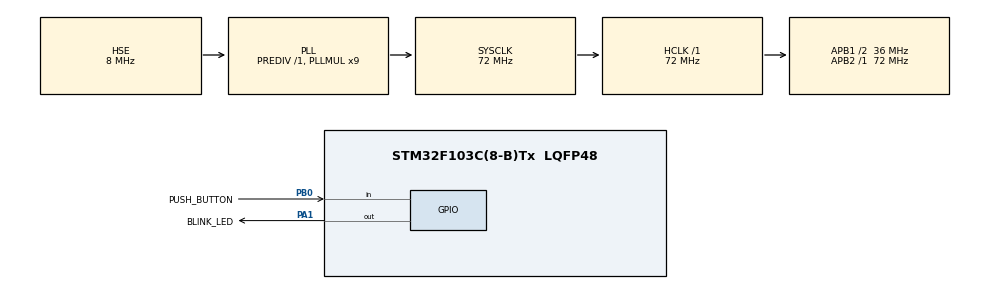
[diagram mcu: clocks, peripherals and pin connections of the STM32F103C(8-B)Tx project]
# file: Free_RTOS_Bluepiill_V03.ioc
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FREERTOS.Tasks01=defaultTask,0,128,StartDefaultTask,Default,NULL,Dynamic,NULL,NULL;ledtask,0,128,LED_Task,Default,NULL,Dynamic,NULL,NULL;buttonTask,0,128,Button_Task,Default,NULL,Dynamic,NULL,NULL
Mcu.Family=STM32F1
Mcu.Name=STM32F103C(8-B)Tx
Mcu.Package=LQFP48
NVIC.PriorityGroup=NVIC_PRIORITYGROUP_4
NVIC.TIM4_IRQn=true\:15\:0\:false\:false\:true\:false\:false\:true\:true
NVIC.TimeBase=TIM4_IRQn
NVIC.TimeBaseIP=TIM4
PA1.GPIO_Label=BLINK_LED
PA1.Signal=GPIO_Output
PA13.Mode=Trace_Asynchronous_SW
PA13.Signal=SYS_JTMS-SWDIO
PA14.Mode=Trace_Asynchronous_SW
PA14.Signal=SYS_JTCK-SWCLK
PB0.GPIO_Label=PUSH_BUTTON
PB0.GPIO_PuPd=GPIO_PULLDOWN
PB0.Signal=GPIO_Input
PB3.Mode=Trace_Asynchronous_SW
PB3.Signal=SYS_JTDO-TRACESWO
PD0-OSC_IN.Mode=HSE-External-Oscillator
PD0-OSC_IN.Signal=RCC_OSC_IN
PD1-OSC_OUT.Mode=HSE-External-Oscillator
PD1-OSC_OUT.Signal=RCC_OSC_OUT
ProjectManager.HeapSize=0x200
ProjectManager.StackSize=0x400
ProjectManager.TargetToolchain=STM32CubeIDE
RCC.AHBFreq_Value=72000000
RCC.APB1CLKDivider=RCC_HCLK_DIV2
RCC.APB1Freq_Value=36000000
RCC.APB1TimFreq_Value=72000000
RCC.APB2Freq_Value=72000000
RCC.APB2TimFreq_Value=72000000
RCC.HCLKFreq_Value=72000000
RCC.PLLMUL=RCC_PLL_MUL9
RCC.PLLSourceVirtual=RCC_PLLSOURCE_HSE
RCC.SYSCLKFreq_VALUE=72000000
RCC.SYSCLKSource=RCC_SYSCLKSOURCE_PLLCLK
RCC.USBFreq_Value=72000000
VP_FREERTOS_VS_CMSIS_V1.Mode=CMSIS_V1
VP_SYS_VS_tim4.Mode=TIM4
board=custom

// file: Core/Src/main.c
/* USER CODE BEGIN Header */
/**
  ******************************************************************************
  * @file           : main.c
  * @brief          : Main program body
  ******************************************************************************
  * @attention
  *
  * Copyright (c) 2024 STMicroelectronics.
  * All rights reserved.
  *
  * This software is licensed under terms that can be found in the LICENSE file
  * in the root directory of this software component.
  * If no LICENSE file comes with this software, it is provided AS-IS.
  *
  ******************************************************************************
  */
/* USER CODE END Header */
#include "main.h"
#include "cmsis_os.h"

osThreadId defaultTaskHandle;
osThreadId ledtaskHandle;
osThreadId buttonTaskHandle;

void SystemClock_Config(void);
static void MX_GPIO_Init(void);
void StartDefaultTask(void const * argument);
void LED_Task(void const * argument);
void Button_Task(void const * argument);

// Variável global para controlar a frequência do LED
uint8_t blinkFrequency = 0;

int main(void)
{

  /* MCU Configuration--------------------------------------------------------*/

  /* Reset of all peripherals, Initializes the Flash interface and the Systick. */
  HAL_Init();

  /* Configure the system clock */
  SystemClock_Config();

  /* Initialize all configured peripherals */
  MX_GPIO_Init();
  /* USER CODE BEGIN 2 */
  // Criar tarefas
      osThreadDef(ButtonTask, Button_Task, osPriorityNormal, 0, 128);
      osThreadCreate(osThread(ButtonTask), NULL);

      osThreadDef(LEDTask, LED_Task, osPriorityNormal, 0, 128);
      osThreadCreate(osThread(LEDTask), NULL);

      // Iniciar o scheduler
      osKernelStart();

  /* USER CODE END 2 */

  /* Create the thread(s) */
  /* definition and creation of defaultTask */
  osThreadDef(defaultTask, StartDefaultTask, osPriorityNormal, 0, 128);
  defaultTaskHandle = osThreadCreate(osThread(defaultTask), NULL);

  /* definition and creation of ledtask */
  osThreadDef(ledtask, LED_Task, osPriorityNormal, 0, 128);
  ledtaskHandle = osThreadCreate(osThread(ledtask), NULL);

  /* definition and creation of buttonTask */
  osThreadDef(buttonTask, Button_Task, osPriorityNormal, 0, 128);
  buttonTaskHandle = osThreadCreate(osThread(buttonTask), NULL);

  /* Start scheduler */
  osKernelStart();

  /* We should never get here as control is now taken by the scheduler */

  /* Infinite loop */
  while (1)
  {

  }
}

void SystemClock_Config(void)
{
  RCC_OscInitTypeDef RCC_OscInitStruct = {0};
  RCC_ClkInitTypeDef RCC_ClkInitStruct = {0};

  /** Initializes the RCC Oscillators according to the specified parameters
  * in the RCC_OscInitTypeDef structure.
  */
  RCC_OscInitStruct.OscillatorType = RCC_OSCILLATORTYPE_HSE;
  RCC_OscInitStruct.HSEState = RCC_HSE_ON;
  RCC_OscInitStruct.HSEPredivValue = RCC_HSE_PREDIV_DIV1;
  RCC_OscInitStruct.HSIState = RCC_HSI_ON;
  RCC_OscInitStruct.PLL.PLLState = RCC_PLL_ON;
  RCC_OscInitStruct.PLL.PLLSource = RCC_PLLSOURCE_HSE;
  RCC_OscInitStruct.PLL.PLLMUL = RCC_PLL_MUL9;
  if (HAL_RCC_OscConfig(&RCC_OscInitStruct) != HAL_OK)
  {
    Error_Handler();
  }

  /** Initializes the CPU, AHB and APB buses clocks
  */
  RCC_ClkInitStruct.ClockType = RCC_CLOCKTYPE_HCLK|RCC_CLOCKTYPE_SYSCLK
                              |RCC_CLOCKTYPE_PCLK1|RCC_CLOCKTYPE_PCLK2;
  RCC_ClkInitStruct.SYSCLKSource = RCC_SYSCLKSOURCE_PLLCLK;
  RCC_ClkInitStruct.AHBCLKDivider = RCC_SYSCLK_DIV1;
  RCC_ClkInitStruct.APB1CLKDivider = RCC_HCLK_DIV2;
  RCC_ClkInitStruct.APB2CLKDivider = RCC_HCLK_DIV1;

  if (HAL_RCC_ClockConfig(&RCC_ClkInitStruct, FLASH_LATENCY_2) != HAL_OK)
  {
    Error_Handler();
  }
}

static void MX_GPIO_Init(void)
{
  GPIO_InitTypeDef GPIO_InitStruct = {0};

  /* GPIO Ports Clock Enable */
  __HAL_RCC_GPIOD_CLK_ENABLE();
  __HAL_RCC_GPIOA_CLK_ENABLE();
  __HAL_RCC_GPIOB_CLK_ENABLE();

  /*Configure GPIO pin Output Level */
  HAL_GPIO_WritePin(BLINK_LED_GPIO_Port, BLINK_LED_Pin, GPIO_PIN_SET);

  /*Configure GPIO pin : BLINK_LED_Pin */
  GPIO_InitStruct.Pin = BLINK_LED_Pin;
  GPIO_InitStruct.Mode = GPIO_MODE_OUTPUT_PP;
  GPIO_InitStruct.Pull = GPIO_NOPULL;
  GPIO_InitStruct.Speed = GPIO_SPEED_FREQ_LOW;
  HAL_GPIO_Init(BLINK_LED_GPIO_Port, &GPIO_InitStruct);

  /*Configure GPIO pin : PUSH_BUTTON_Pin */
  GPIO_InitStruct.Pin = PUSH_BUTTON_Pin;
  GPIO_InitStruct.Mode = GPIO_MODE_INPUT;
  GPIO_InitStruct.Pull = GPIO_PULLDOWN;
  HAL_GPIO_Init(PUSH_BUTTON_GPIO_Port, &GPIO_InitStruct);

}

void StartDefaultTask(void const * argument)
{
  for(;;)
  {
    osDelay(1);
  }
}

void LED_Task(void const * argument)
{
	extern uint8_t blinkFrequency;

	    while (1) {
	        switch (blinkFrequency) {
	            case 0: // LED desligado
	                HAL_GPIO_WritePin(BLINK_LED_GPIO_Port, BLINK_LED_Pin, GPIO_PIN_SET);
	                osDelay(100); // Pequeno atraso para evitar alto consumo de CPU
	                break;
	            case 1: // Piscar a 1 Hz
	                HAL_GPIO_TogglePin(BLINK_LED_GPIO_Port, BLINK_LED_Pin);
	                osDelay(500); // 500 ms on/off
	                break;
	            case 2: // Piscar a 10 Hz
	                HAL_GPIO_TogglePin(BLINK_LED_GPIO_Port, BLINK_LED_Pin);
	                osDelay(50); // 50 ms on/off
	                break;

	            case 3: // Piscar a 20 Hz
					HAL_GPIO_TogglePin(BLINK_LED_GPIO_Port, BLINK_LED_Pin);
					osDelay(25); // 50 ms on/off
					break;
	        }
	    }

}

void Button_Task(void const * argument)
{
	static uint8_t lastButtonState = 0;
	    extern uint8_t blinkFrequency;

	    while (1) {
	        uint8_t currentState = HAL_GPIO_ReadPin(PUSH_BUTTON_GPIO_Port, PUSH_BUTTON_Pin);
	        if (currentState == GPIO_PIN_SET && lastButtonState == GPIO_PIN_RESET) {
	            // Botão pressionado - altera a frequência do LED
	            blinkFrequency = (blinkFrequency + 1) % 4; // Alterna entre 0 (apagado), 1 (1 Hz) e 2 (10 Hz)
	        }
	        lastButtonState = currentState;
	        osDelay(50); // Debounce do botão
	    }
}

void HAL_TIM_PeriodElapsedCallback(TIM_HandleTypeDef *htim)
{
  if (htim->Instance == TIM4) {
    HAL_IncTick();
  }
}

void Error_Handler(void)
{
  __disable_irq();
  while (1)
  {
  }
}
